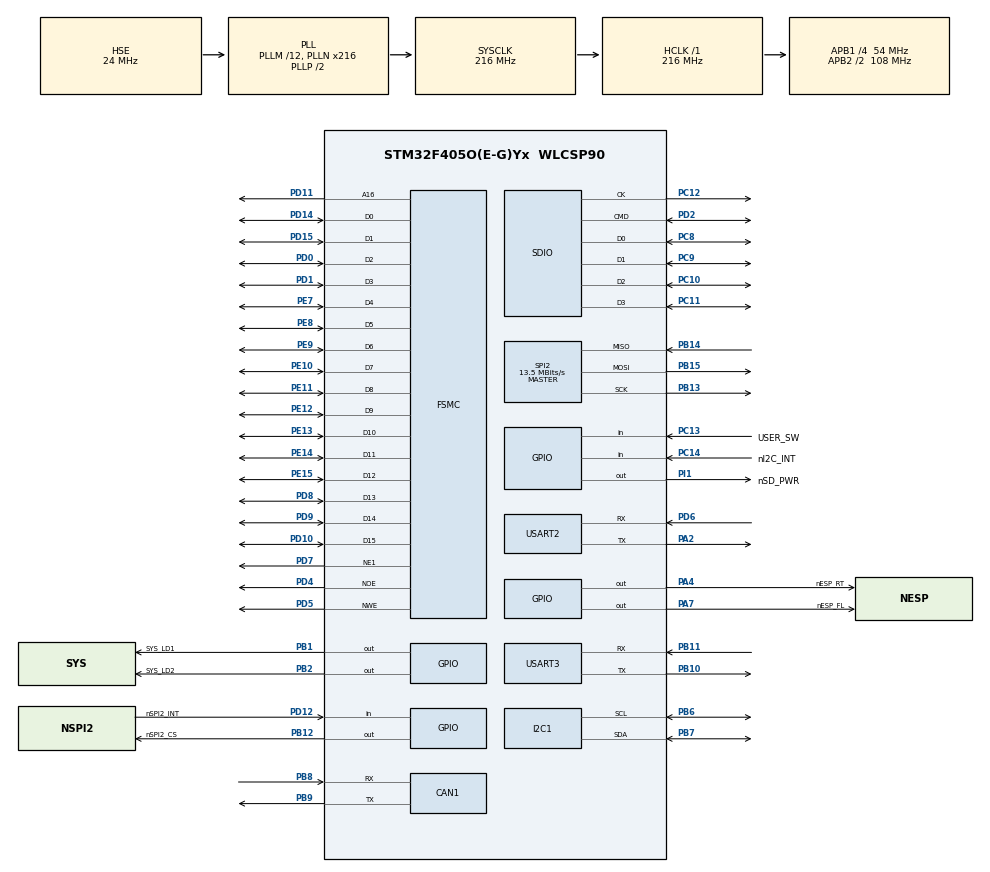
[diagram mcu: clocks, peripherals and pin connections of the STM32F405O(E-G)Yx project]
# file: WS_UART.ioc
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CAN1.BS1=CAN_BS1_3TQ
CAN1.BS2=CAN_BS2_1TQ
CAN1.CalculateTimeQuantum=296.2962962962963
Dma.Request0=SDIO_RX
Dma.Request1=SDIO_TX
Dma.SDIO_RX.0.Direction=DMA_PERIPH_TO_MEMORY
Dma.SDIO_RX.0.FIFOMode=DMA_FIFOMODE_ENABLE
Dma.SDIO_RX.0.FIFOThreshold=DMA_FIFO_THRESHOLD_FULL
Dma.SDIO_RX.0.Instance=DMA2_Stream3
Dma.SDIO_RX.0.MemBurst=DMA_MBURST_INC4
Dma.SDIO_RX.0.MemDataAlignment=DMA_MDATAALIGN_WORD
Dma.SDIO_RX.0.MemInc=DMA_MINC_ENABLE
Dma.SDIO_RX.0.Mode=DMA_PFCTRL
Dma.SDIO_RX.0.PeriphBurst=DMA_PBURST_INC4
Dma.SDIO_RX.0.PeriphDataAlignment=DMA_PDATAALIGN_WORD
Dma.SDIO_RX.0.PeriphInc=DMA_PINC_DISABLE
Dma.SDIO_RX.0.Priority=DMA_PRIORITY_LOW
Dma.SDIO_TX.1.Direction=DMA_MEMORY_TO_PERIPH
Dma.SDIO_TX.1.FIFOMode=DMA_FIFOMODE_ENABLE
Dma.SDIO_TX.1.FIFOThreshold=DMA_FIFO_THRESHOLD_FULL
Dma.SDIO_TX.1.Instance=DMA2_Stream6
Dma.SDIO_TX.1.MemBurst=DMA_MBURST_INC4
Dma.SDIO_TX.1.MemDataAlignment=DMA_MDATAALIGN_WORD
Dma.SDIO_TX.1.MemInc=DMA_MINC_ENABLE
Dma.SDIO_TX.1.Mode=DMA_PFCTRL
Dma.SDIO_TX.1.PeriphBurst=DMA_PBURST_INC4
Dma.SDIO_TX.1.PeriphDataAlignment=DMA_PDATAALIGN_WORD
Dma.SDIO_TX.1.PeriphInc=DMA_PINC_DISABLE
Dma.SDIO_TX.1.Priority=DMA_PRIORITY_LOW
FATFS._CODE_PAGE=437
FATFS._USE_FIND=1
FATFS._USE_LABEL=1
FATFS._USE_LFN=1
Mcu.Family=STM32F4
Mcu.Name=STM32F405O(E-G)Yx
Mcu.Package=WLCSP90
NVIC.DMA2_Stream3_IRQn=true\:1\:0\:true\:false\:true\:false
NVIC.DMA2_Stream6_IRQn=true\:1\:0\:true\:false\:true\:false
NVIC.PriorityGroup=NVIC_PRIORITYGROUP_4
PA2.Mode=Asynchronous
PA2.Signal=USART2_TX
PA4.GPIO_Label=nESP_RT
PA4.Signal=GPIO_Output
PA7.GPIO_Label=nESP_FL
PA7.Signal=GPIO_Output
PB1.GPIO_Label=SYS_LD1
PB1.Signal=GPIO_Output
PB10.Mode=Asynchronous
PB10.Signal=USART3_TX
PB11.Mode=Asynchronous
PB11.Signal=USART3_RX
PB12.GPIO_Label=nSPI2_CS
PB12.Signal=GPIO_Output
PB13.Mode=Full_Duplex_Master
PB13.Signal=SPI2_SCK
PB14.Mode=Full_Duplex_Master
PB14.Signal=SPI2_MISO
PB15.Mode=Full_Duplex_Master
PB15.Signal=SPI2_MOSI
PB2.GPIO_Label=SYS_LD2
PB2.Signal=GPIO_Output
PB6.Mode=I2C
PB6.Signal=I2C1_SCL
PB7.Mode=I2C
PB7.Signal=I2C1_SDA
PB8.Mode=Master
PB8.Signal=CAN1_RX
PB9.Mode=Master
PB9.Signal=CAN1_TX
PC10.GPIO_PuPd=GPIO_NOPULL
PC10.Mode=SD_4_bits_Wide_bus
PC10.Signal=SDIO_D2
PC11.GPIO_PuPd=GPIO_NOPULL
PC11.Mode=SD_4_bits_Wide_bus
PC11.Signal=SDIO_D3
PC12.GPIO_PuPd=GPIO_NOPULL
PC12.Mode=SD_4_bits_Wide_bus
PC12.Signal=SDIO_CK
PC13-ANTI_TAMP.GPIO_Label=USER_SW
PC13-ANTI_TAMP.Signal=GPIO_Input
PC14-OSC32_IN.GPIO_Label=nI2C_INT
PC14-OSC32_IN.Signal=GPIO_Input
PC8.GPIO_PuPd=GPIO_NOPULL
PC8.Mode=SD_4_bits_Wide_bus
PC8.Signal=SDIO_D0
PC9.GPIO_PuPd=GPIO_NOPULL
PC9.Mode=SD_4_bits_Wide_bus
PC9.Signal=SDIO_D1
PD0.Mode=16b-d1
PD0.Signal=FSMC_D2
PD1.Mode=16b-d1
PD1.Signal=FSMC_D3
PD10.Mode=16b-d1
PD10.Signal=FSMC_D15
PD11.Mode=A16_1
PD11.Signal=FSMC_A16
PD12.GPIO_Label=nSPI2_INT
PD12.Signal=GPIO_Input
PD14.Mode=16b-d1
PD14.Signal=FSMC_D0
PD15.Mode=16b-d1
PD15.Signal=FSMC_D1
PD2.GPIO_PuPd=GPIO_NOPULL
PD2.Mode=SD_4_bits_Wide_bus
PD2.Signal=SDIO_CMD
PD4.Mode=Lcd1
PD4.Signal=FSMC_NOE
PD5.Mode=Lcd1
PD5.Signal=FSMC_NWE
PD6.Mode=Asynchronous
PD6.Signal=USART2_RX
PD7.Mode=NorPsramChipSelect1_1
PD7.Signal=FSMC_NE1
PD8.Mode=16b-d1
PD8.Signal=FSMC_D13
PD9.Mode=16b-d1
PD9.Signal=FSMC_D14
PE10.Mode=16b-d1
PE10.Signal=FSMC_D7
PE11.Mode=16b-d1
PE11.Signal=FSMC_D8
PE12.Mode=16b-d1
PE12.Signal=FSMC_D9
PE13.Mode=16b-d1
PE13.Signal=FSMC_D10
PE14.Mode=16b-d1
PE14.Signal=FSMC_D11
PE15.Mode=16b-d1
PE15.Signal=FSMC_D12
PE7.Mode=16b-d1
PE7.Signal=FSMC_D4
PE8.Mode=16b-d1
PE8.Signal=FSMC_D5
PE9.Mode=16b-d1
PE9.Signal=FSMC_D6
PH0-OSC_IN.Mode=HSE-External-Oscillator
PH0-OSC_IN.Signal=RCC_OSC_IN
PH1-OSC_OUT.Mode=HSE-External-Oscillator
PH1-OSC_OUT.Signal=RCC_OSC_OUT
PI1.GPIO_Label=nSD_PWR
PI1.GPIO_PuPd=GPIO_PULLDOWN
PI1.Signal=GPIO_Output
ProjectManager.HeapSize=0x8000
ProjectManager.StackSize=0x4000
ProjectManager.TargetToolchain=MDK-ARM V5
RCC.48MHZClocksFreq_Value=48000000
RCC.AHBFreq_Value=216000000
RCC.APB1CLKDivider=RCC_HCLK_DIV4
RCC.APB1Freq_Value=54000000
RCC.APB1TimFreq_Value=108000000
RCC.APB2CLKDivider=RCC_HCLK_DIV2
RCC.APB2Freq_Value=108000000
RCC.APB2TimFreq_Value=216000000
RCC.CortexFreq_Value=216000000
RCC.HCLKFreq_Value=216000000
RCC.HSE_VALUE=24000000
RCC.HSI_VALUE=16000000
RCC.LSE_VALUE=32768
RCC.PLLM=12
RCC.PLLN=216
RCC.PLLQ=9
RCC.PLLSourceVirtual=RCC_PLLSOURCE_HSE
RCC.SYSCLKFreq_VALUE=216000000
RCC.SYSCLKSource=RCC_SYSCLKSOURCE_PLLCLK
RCC.VCOOutputFreq_Value=432000000
SDIO.ClockDiv=0
SPI2.BaudRatePrescaler=SPI_BAUDRATEPRESCALER_4
SPI2.CalculateBaudRate=13.5 MBits/s
SPI2.Direction=SPI_DIRECTION_2LINES
SPI2.Mode=SPI_MODE_MASTER
SPI2.VirtualType=VM_MASTER
USART2.VirtualMode=VM_ASYNC
USART3.VirtualMode=VM_ASYNC
VP_FATFS_VS_SDIO.Mode=SDIO
board=custom

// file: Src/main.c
/* USER CODE BEGIN Header */
/**
  ******************************************************************************
  * @file           : main.c
  * @brief          : Main program body
  ******************************************************************************
  * This notice applies to any and all portions of this file
  * that are not between comment pairs USER CODE BEGIN and
  * USER CODE END. Other portions of this file, whether
  * inserted by the user or by software development tools
  * are owned by their respective copyright owners.
  *
  * Copyright (c) 2018 STMicroelectronics International N.V.
  * All rights reserved.
  *
  * Redistribution and use in source and binary forms, with or without
  * modification, are permitted, provided that the following conditions are met:
  *
  * 1. Redistribution of source code must retain the above copyright notice,
  *    this list of conditions and the following disclaimer.
  * 2. Redistributions in binary form must reproduce the above copyright notice,
  *    this list of conditions and the following disclaimer in the documentation
  *    and/or other materials provided with the distribution.
  * 3. Neither the name of STMicroelectronics nor the names of other
  *    contributors to this software may be used to endorse or promote products
  *    derived from this software without specific written permission.
  * 4. This software, including modifications and/or derivative works of this
  *    software, must execute solely and exclusively on microcontroller or
  *    microprocessor devices manufactured by or for STMicroelectronics.
  * 5. Redistribution and use of this software other than as permitted under
  *    this license is void and will automatically terminate your rights under
  *    this license.
  *
  * THIS SOFTWARE IS PROVIDED BY STMICROELECTRONICS AND CONTRIBUTORS "AS IS"
  * AND ANY EXPRESS, IMPLIED OR STATUTORY WARRANTIES, INCLUDING, BUT NOT
  * LIMITED TO, THE IMPLIED WARRANTIES OF MERCHANTABILITY, FITNESS FOR A
  * PARTICULAR PURPOSE AND NON-INFRINGEMENT OF THIRD PARTY INTELLECTUAL PROPERTY
  * RIGHTS ARE DISCLAIMED TO THE FULLEST EXTENT PERMITTED BY LAW. IN NO EVENT
  * SHALL STMICROELECTRONICS OR CONTRIBUTORS BE LIABLE FOR ANY DIRECT, INDIRECT,
  * INCIDENTAL, SPECIAL, EXEMPLARY, OR CONSEQUENTIAL DAMAGES (INCLUDING, BUT NOT
  * LIMITED TO, PROCUREMENT OF SUBSTITUTE GOODS OR SERVICES; LOSS OF USE, DATA,
  * OR PROFITS; OR BUSINESS INTERRUPTION) HOWEVER CAUSED AND ON ANY THEORY OF
  * LIABILITY, WHETHER IN CONTRACT, STRICT LIABILITY, OR TORT (INCLUDING
  * NEGLIGENCE OR OTHERWISE) ARISING IN ANY WAY OUT OF THE USE OF THIS SOFTWARE,
  * EVEN IF ADVISED OF THE POSSIBILITY OF SUCH DAMAGE.
  *
  ******************************************************************************
  */
/* USER CODE END Header */

#include "main.h"
#include "fatfs.h"

CAN_HandleTypeDef hcan1;

I2C_HandleTypeDef hi2c1;

SD_HandleTypeDef hsd;
DMA_HandleTypeDef hdma_sdio_rx;
DMA_HandleTypeDef hdma_sdio_tx;

SPI_HandleTypeDef hspi2;

UART_HandleTypeDef huart2;
UART_HandleTypeDef huart3;

SRAM_HandleTypeDef hsram1;

void SystemClock_Config(void);
static void MX_GPIO_Init(void);
static void MX_DMA_Init(void);
static void MX_SDIO_SD_Init(void);
static void MX_USART3_UART_Init(void);
static void MX_FSMC_Init(void);
static void MX_USART2_UART_Init(void);
static void MX_CAN1_Init(void);
static void MX_I2C1_Init(void);
static void MX_SPI2_Init(void);

/* USER CODE BEGIN 0 */
#ifdef __GNUC__
 #define PUTCHAR_PROTOTYPE int __io_putchar(int ch)
#else
 #define PUTCHAR_PROTOTYPE int fputc(int ch, FILE *f)
#endif

PUTCHAR_PROTOTYPE
{
 HAL_UART_Transmit(&huart2, (uint8_t *)&ch, 1, 1);
 return ch;
}
/* USER CODE END 0 */

int main(void)
{

  /* MCU Configuration--------------------------------------------------------*/

  /* Reset of all peripherals, Initializes the Flash interface and the Systick. */
  HAL_Init();

  /* Configure the system clock */
  SystemClock_Config();

  /* Initialize all configured peripherals */
  MX_GPIO_Init();
  MX_DMA_Init();
  MX_SDIO_SD_Init();
  MX_USART3_UART_Init();
  MX_FSMC_Init();
  MX_USART2_UART_Init();
  MX_CAN1_Init();
  MX_I2C1_Init();
  MX_SPI2_Init();
  MX_FATFS_Init();

  /* Infinite loop */
  /* USER CODE BEGIN WHILE */
  while (1)
  {
		HAL_GPIO_TogglePin(SYS_LD1_GPIO_Port,SYS_LD1_Pin);
		HAL_GPIO_TogglePin(SYS_LD2_GPIO_Port,SYS_LD2_Pin);
		printf("UART Test Out.. !! every 100ms\n\r");
		HAL_Delay(100);
    /* USER CODE END WHILE */

  }
}

void SystemClock_Config(void)
{
  RCC_OscInitTypeDef RCC_OscInitStruct = {0};
  RCC_ClkInitTypeDef RCC_ClkInitStruct = {0};

  /**Configure the main internal regulator output voltage
  */
  __HAL_RCC_PWR_CLK_ENABLE();
  __HAL_PWR_VOLTAGESCALING_CONFIG(PWR_REGULATOR_VOLTAGE_SCALE1);
  /**Initializes the CPU, AHB and APB busses clocks
  */
  RCC_OscInitStruct.OscillatorType = RCC_OSCILLATORTYPE_HSE;
  RCC_OscInitStruct.HSEState = RCC_HSE_ON;
  RCC_OscInitStruct.PLL.PLLState = RCC_PLL_ON;
  RCC_OscInitStruct.PLL.PLLSource = RCC_PLLSOURCE_HSE;
  RCC_OscInitStruct.PLL.PLLM = 12;
  RCC_OscInitStruct.PLL.PLLN = 216;
  RCC_OscInitStruct.PLL.PLLP = RCC_PLLP_DIV2;
  RCC_OscInitStruct.PLL.PLLQ = 9;
  if (HAL_RCC_OscConfig(&RCC_OscInitStruct) != HAL_OK)
  {
    Error_Handler();
  }
  /**Initializes the CPU, AHB and APB busses clocks
  */
  RCC_ClkInitStruct.ClockType = RCC_CLOCKTYPE_HCLK|RCC_CLOCKTYPE_SYSCLK
                              |RCC_CLOCKTYPE_PCLK1|RCC_CLOCKTYPE_PCLK2;
  RCC_ClkInitStruct.SYSCLKSource = RCC_SYSCLKSOURCE_PLLCLK;
  RCC_ClkInitStruct.AHBCLKDivider = RCC_SYSCLK_DIV1;
  RCC_ClkInitStruct.APB1CLKDivider = RCC_HCLK_DIV4;
  RCC_ClkInitStruct.APB2CLKDivider = RCC_HCLK_DIV2;

  if (HAL_RCC_ClockConfig(&RCC_ClkInitStruct, FLASH_LATENCY_5) != HAL_OK)
  {
    Error_Handler();
  }
}

static void MX_CAN1_Init(void)
{

  hcan1.Instance = CAN1;
  hcan1.Init.Prescaler = 16;
  hcan1.Init.Mode = CAN_MODE_NORMAL;
  hcan1.Init.SyncJumpWidth = CAN_SJW_1TQ;
  hcan1.Init.TimeSeg1 = CAN_BS1_3TQ;
  hcan1.Init.TimeSeg2 = CAN_BS2_1TQ;
  hcan1.Init.TimeTriggeredMode = DISABLE;
  hcan1.Init.AutoBusOff = DISABLE;
  hcan1.Init.AutoWakeUp = DISABLE;
  hcan1.Init.AutoRetransmission = DISABLE;
  hcan1.Init.ReceiveFifoLocked = DISABLE;
  hcan1.Init.TransmitFifoPriority = DISABLE;
  if (HAL_CAN_Init(&hcan1) != HAL_OK)
  {
    Error_Handler();
  }

}

static void MX_I2C1_Init(void)
{

  hi2c1.Instance = I2C1;
  hi2c1.Init.ClockSpeed = 100000;
  hi2c1.Init.DutyCycle = I2C_DUTYCYCLE_2;
  hi2c1.Init.OwnAddress1 = 0;
  hi2c1.Init.AddressingMode = I2C_ADDRESSINGMODE_7BIT;
  hi2c1.Init.DualAddressMode = I2C_DUALADDRESS_DISABLE;
  hi2c1.Init.OwnAddress2 = 0;
  hi2c1.Init.GeneralCallMode = I2C_GENERALCALL_DISABLE;
  hi2c1.Init.NoStretchMode = I2C_NOSTRETCH_DISABLE;
  if (HAL_I2C_Init(&hi2c1) != HAL_OK)
  {
    Error_Handler();
  }

}

static void MX_SDIO_SD_Init(void)
{

  hsd.Instance = SDIO;
  hsd.Init.ClockEdge = SDIO_CLOCK_EDGE_RISING;
  hsd.Init.ClockBypass = SDIO_CLOCK_BYPASS_DISABLE;
  hsd.Init.ClockPowerSave = SDIO_CLOCK_POWER_SAVE_DISABLE;
  hsd.Init.BusWide = SDIO_BUS_WIDE_1B;
  hsd.Init.HardwareFlowControl = SDIO_HARDWARE_FLOW_CONTROL_DISABLE;
  hsd.Init.ClockDiv = 0;

}

static void MX_SPI2_Init(void)
{

  /* SPI2 parameter configuration*/
  hspi2.Instance = SPI2;
  hspi2.Init.Mode = SPI_MODE_MASTER;
  hspi2.Init.Direction = SPI_DIRECTION_2LINES;
  hspi2.Init.DataSize = SPI_DATASIZE_8BIT;
  hspi2.Init.CLKPolarity = SPI_POLARITY_LOW;
  hspi2.Init.CLKPhase = SPI_PHASE_1EDGE;
  hspi2.Init.NSS = SPI_NSS_SOFT;
  hspi2.Init.BaudRatePrescaler = SPI_BAUDRATEPRESCALER_4;
  hspi2.Init.FirstBit = SPI_FIRSTBIT_MSB;
  hspi2.Init.TIMode = SPI_TIMODE_DISABLE;
  hspi2.Init.CRCCalculation = SPI_CRCCALCULATION_DISABLE;
  hspi2.Init.CRCPolynomial = 10;
  if (HAL_SPI_Init(&hspi2) != HAL_OK)
  {
    Error_Handler();
  }

}

static void MX_USART2_UART_Init(void)
{

  huart2.Instance = USART2;
  huart2.Init.BaudRate = 115200;
  huart2.Init.WordLength = UART_WORDLENGTH_8B;
  huart2.Init.StopBits = UART_STOPBITS_1;
  huart2.Init.Parity = UART_PARITY_NONE;
  huart2.Init.Mode = UART_MODE_TX_RX;
  huart2.Init.HwFlowCtl = UART_HWCONTROL_NONE;
  huart2.Init.OverSampling = UART_OVERSAMPLING_16;
  if (HAL_UART_Init(&huart2) != HAL_OK)
  {
    Error_Handler();
  }

}

static void MX_USART3_UART_Init(void)
{

  huart3.Instance = USART3;
  huart3.Init.BaudRate = 115200;
  huart3.Init.WordLength = UART_WORDLENGTH_8B;
  huart3.Init.StopBits = UART_STOPBITS_1;
  huart3.Init.Parity = UART_PARITY_NONE;
  huart3.Init.Mode = UART_MODE_TX_RX;
  huart3.Init.HwFlowCtl = UART_HWCONTROL_NONE;
  huart3.Init.OverSampling = UART_OVERSAMPLING_16;
  if (HAL_UART_Init(&huart3) != HAL_OK)
  {
    Error_Handler();
  }

}

static void MX_DMA_Init(void)
{
  /* DMA controller clock enable */
  __HAL_RCC_DMA2_CLK_ENABLE();

  /* DMA interrupt init */
  /* DMA2_Stream3_IRQn interrupt configuration */
  HAL_NVIC_SetPriority(DMA2_Stream3_IRQn, 1, 0);
  HAL_NVIC_EnableIRQ(DMA2_Stream3_IRQn);
  /* DMA2_Stream6_IRQn interrupt configuration */
  HAL_NVIC_SetPriority(DMA2_Stream6_IRQn, 1, 0);
  HAL_NVIC_EnableIRQ(DMA2_Stream6_IRQn);

}

static void MX_GPIO_Init(void)
{
  GPIO_InitTypeDef GPIO_InitStruct = {0};

  /* GPIO Ports Clock Enable */
  __HAL_RCC_GPIOC_CLK_ENABLE();
  __HAL_RCC_GPIOD_CLK_ENABLE();
  __HAL_RCC_GPIOI_CLK_ENABLE();
  __HAL_RCC_GPIOB_CLK_ENABLE();
  __HAL_RCC_GPIOE_CLK_ENABLE();
  __HAL_RCC_GPIOH_CLK_ENABLE();
  __HAL_RCC_GPIOA_CLK_ENABLE();

  /*Configure GPIO pin Output Level */
  HAL_GPIO_WritePin(nSD_PWR_GPIO_Port, nSD_PWR_Pin, GPIO_PIN_RESET);

  /*Configure GPIO pin Output Level */
  HAL_GPIO_WritePin(GPIOB, SYS_LD1_Pin|nSPI2_CS_Pin|SYS_LD2_Pin, GPIO_PIN_RESET);

  /*Configure GPIO pin Output Level */
  HAL_GPIO_WritePin(GPIOA, nESP_FL_Pin|nESP_RT_Pin, GPIO_PIN_RESET);

  /*Configure GPIO pins : USER_SW_Pin nI2C_INT_Pin */
  GPIO_InitStruct.Pin = USER_SW_Pin|nI2C_INT_Pin;
  GPIO_InitStruct.Mode = GPIO_MODE_INPUT;
  GPIO_InitStruct.Pull = GPIO_NOPULL;
  HAL_GPIO_Init(GPIOC, &GPIO_InitStruct);

  /*Configure GPIO pin : nSD_PWR_Pin */
  GPIO_InitStruct.Pin = nSD_PWR_Pin;
  GPIO_InitStruct.Mode = GPIO_MODE_OUTPUT_PP;
  GPIO_InitStruct.Pull = GPIO_PULLDOWN;
  GPIO_InitStruct.Speed = GPIO_SPEED_FREQ_LOW;
  HAL_GPIO_Init(nSD_PWR_GPIO_Port, &GPIO_InitStruct);

  /*Configure GPIO pin : nSPI2_INT_Pin */
  GPIO_InitStruct.Pin = nSPI2_INT_Pin;
  GPIO_InitStruct.Mode = GPIO_MODE_INPUT;
  GPIO_InitStruct.Pull = GPIO_NOPULL;
  HAL_GPIO_Init(nSPI2_INT_GPIO_Port, &GPIO_InitStruct);

  /*Configure GPIO pins : SYS_LD1_Pin nSPI2_CS_Pin SYS_LD2_Pin */
  GPIO_InitStruct.Pin = SYS_LD1_Pin|nSPI2_CS_Pin|SYS_LD2_Pin;
  GPIO_InitStruct.Mode = GPIO_MODE_OUTPUT_PP;
  GPIO_InitStruct.Pull = GPIO_NOPULL;
  GPIO_InitStruct.Speed = GPIO_SPEED_FREQ_LOW;
  HAL_GPIO_Init(GPIOB, &GPIO_InitStruct);

  /*Configure GPIO pins : nESP_FL_Pin nESP_RT_Pin */
  GPIO_InitStruct.Pin = nESP_FL_Pin|nESP_RT_Pin;
  GPIO_InitStruct.Mode = GPIO_MODE_OUTPUT_PP;
  GPIO_InitStruct.Pull = GPIO_NOPULL;
  GPIO_InitStruct.Speed = GPIO_SPEED_FREQ_LOW;
  HAL_GPIO_Init(GPIOA, &GPIO_InitStruct);

}

/* FSMC initialization function */
static void MX_FSMC_Init(void)
{
  FSMC_NORSRAM_TimingTypeDef Timing;

  /** Perform the SRAM1 memory initialization sequence
  */
  hsram1.Instance = FSMC_NORSRAM_DEVICE;
  hsram1.Extended = FSMC_NORSRAM_EXTENDED_DEVICE;
  /* hsram1.Init */
  hsram1.Init.NSBank = FSMC_NORSRAM_BANK1;
  hsram1.Init.DataAddressMux = FSMC_DATA_ADDRESS_MUX_DISABLE;
  hsram1.Init.MemoryType = FSMC_MEMORY_TYPE_SRAM;
  hsram1.Init.MemoryDataWidth = FSMC_NORSRAM_MEM_BUS_WIDTH_16;
  hsram1.Init.BurstAccessMode = FSMC_BURST_ACCESS_MODE_DISABLE;
  hsram1.Init.WaitSignalPolarity = FSMC_WAIT_SIGNAL_POLARITY_LOW;
  hsram1.Init.WrapMode = FSMC_WRAP_MODE_DISABLE;
  hsram1.Init.WaitSignalActive = FSMC_WAIT_TIMING_BEFORE_WS;
  hsram1.Init.WriteOperation = FSMC_WRITE_OPERATION_ENABLE;
  hsram1.Init.WaitSignal = FSMC_WAIT_SIGNAL_DISABLE;
  hsram1.Init.ExtendedMode = FSMC_EXTENDED_MODE_DISABLE;
  hsram1.Init.AsynchronousWait = FSMC_ASYNCHRONOUS_WAIT_DISABLE;
  hsram1.Init.WriteBurst = FSMC_WRITE_BURST_DISABLE;
  hsram1.Init.PageSize = FSMC_PAGE_SIZE_NONE;
  /* Timing */
  Timing.AddressSetupTime = 15;
  Timing.AddressHoldTime = 15;
  Timing.DataSetupTime = 255;
  Timing.BusTurnAroundDuration = 15;
  Timing.CLKDivision = 16;
  Timing.DataLatency = 17;
  Timing.AccessMode = FSMC_ACCESS_MODE_A;
  /* ExtTiming */

  if (HAL_SRAM_Init(&hsram1, &Timing, NULL) != HAL_OK)
  {
    Error_Handler( );
  }

}

void Error_Handler(void)
{
}

/************************ (C) COPYRIGHT STMicroelectronics *****END OF FILE****/
